# K1921VG1T register map
Vendor: NIIET; Series: K1921VGx; File version: 2.8
CPU: other r0p1, little endian, MPU, FPU, 4 interrupt priority bits
Registers are 32-bit, read-write, reset 0x0 unless marked. A register's access mark holds for its fields unless they carry their own. Offsets are from the block's base; [hi:lo] are bit positions; 'fields as' and 'values as' point back to an identical list.

## ETH — Ethernet control registers
Base 0x5000B000
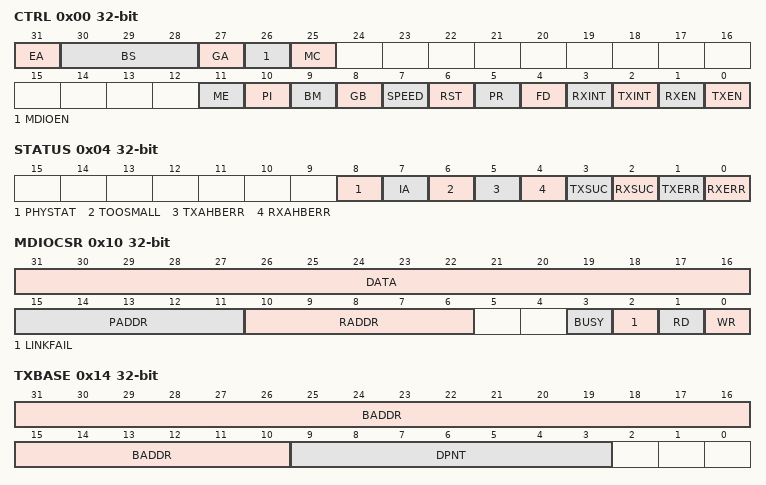
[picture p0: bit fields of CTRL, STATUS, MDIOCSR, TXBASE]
0x00 CTRL — Ethernet control and capabilities register
  [31] EA ro — EDCL available
  [30:28] BS ro — EDCL buffer size
  [27] GA ro — Gigabit MAC available
  [26] MDIOEN ro — MDIO interrupt enabled
  [25] MC ro — Multicast available
  [11] ME — Multicast enable
  [10] PI — PHY status change irq enable
  [9] BM — Burstmode
  [8] GB — Gigabit
  [7] SPEED
  [6] RST — Reset
  [5] PR — Promiscuous mode
  [4] FD — Full duplex
  [3] RXINT — Receiver interrupt
  [2] TXINT — Transmitter interrupt
  [1] RXEN — Receive enable
  [0] TXEN — Transmit enable
0x04 STATUS — Ethernet status register
  [8] PHYSTAT — PHY status changes
  [7] IA — Invalid address
  [6] TOOSMALL
  [5] TXAHBERR — Transmitter AHB error
  [4] RXAHBERR — Receiver AHB error
  [3] TXSUC — Transmit successful
  [2] RXSUC — Receive successful
  [1] TXERR — Transmitter error
  [0] RXERR — Receiver error
0x08 MACMSB — Ethernet MAC address high bytes
  [15:0] VAL
0x0C MACLSB — Ethernet MAC address low bytes
  [31:0] VAL
0x10 MDIOCSR — MDIO control & status register
  [31:16] DATA — MDIO Data
  [15:11] PADDR — PHY address
  [10:6] RADDR — Register address
  [3] BUSY ro
  [2] LINKFAIL ro
  [1] RD — Read
  [0] WR — Wirte
0x14 TXBASE — Transmitter descriptor table base address pointer
  [31:10] BADDR — Transmitter descriptor table base address
  [9:3] DPNT — Descriptor pointer
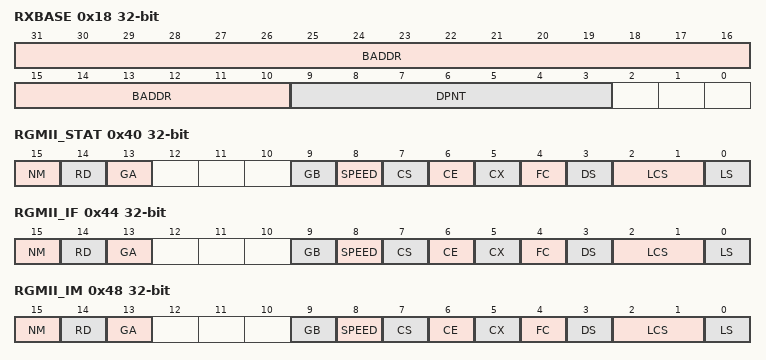
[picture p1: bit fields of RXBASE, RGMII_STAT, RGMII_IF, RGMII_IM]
0x18 RXBASE — Receiver descriptor table base address pointer
  [31:10] BADDR — Receiver descriptor table base address
  [9:3] DPNT — Descriptor pointer
0x40 RGMII_STAT ro — RGMII Status register
  [15] NM — No Clock Mux mode
  [14] RD — RAM debug enable
  [13] GA — Gigabit MAC available
  [9] GB — Gigabit
  [8] SPEED — MAC Speed
  [7] CS — Carrier sence
  [6] CE — Carrier extended frames error
  [5] CX — Carrier extended
  [4] FC — False Carrier is detected
  [3] DS — Duplex Status
    0=HALF_DUPLEX (Half-duplex status); 1=FULL_DUPLEX (Full-duplex status)
  [2:1] LCS — Line Clock Speed
    0=10MBIT (2.5 MHz RXC Clock speed); 1=100MBIT (25 MHz RXC Clock speed); 2=1G (125MHz RXC Clock speed)
  [0] LS — Link Status
    0=DOWN; 1=UP
0x44 RGMII_IF ro — RGMII Interrupt flag register
  fields as RGMII_STAT
0x48 RGMII_IM — RGMII interrupt mask register
  fields as RGMII_STAT
0x4C WRAP_100M — RGMII 25MHz clock wrap register
  [5:0] WRAP — Number of GTX_CLK cycles to generate 25Mhz clock pattern
0x50 EDGE1_100M — RGMII 25 MHz first edge register
  [5:0] EDGE1 — Number of GTX_CLK cycles to before clock change state
0x54 EDGE2_100M — RGMII 25 MHz second edge register
  [5:0] EDGE2 — Number of GTX_CLK cycles after the first edge the clock change state
0x58 WRAP_10M — RGMII 2.5MHz clock wrap register
  fields as WRAP_100M
0x5C EDGE1_10M — RGMII 2.5 MHz first edge register
  [5:0] EDGE1 — Number of GTX_CLK cycles to before clock change state
0x60 EDGE2_10M — RGMII 2.5 MHz second edge register
  fields as EDGE2_100M
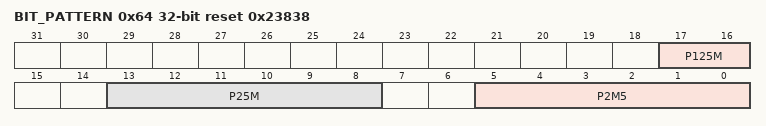
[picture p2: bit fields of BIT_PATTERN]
0x64 BIT_PATTERN reset 0x23838 — RGMII bit pattern register
  [17:16] P125M — Pattern for generating 125Mhz clock
  [13:8] P25M — Pattern for generating 25Mhz clock
  [5:0] P2M5 — Pattern for generating 2.5Mhz clock
0x68 NEG_DELAY — RGMII positive clock data receiver delay register
  [1:0] DELAY — Number of RX clock cycles to delay input data
0x6C POS_DELAY — RGMII negative clock data receiver delay register
  [1:0] DELAY — Number of RX clock cycles to delay input data
0x70 BIT_SWAP — RGMII receiver sample order swap register
  [0] SWAP — Change data order on RxD RGMII to GMII output
0x74 DATA_SWAP — RGMII receiver data swap register
  [0] SWAP — Swaps data between negative and positive clocked data input
0x78 CTRL_SWAP — RGMII receiver control signal swap register
  [0] SWAP — Swaps control signals lines RX_DV and RXC
0x7C PHYCFG reset 0x1 — ETH PHY control register
  [0] EXTPHY — Use external PHY Layer
